VERSION ""

NS_ :

BS_:

BU_: C_LAM_01

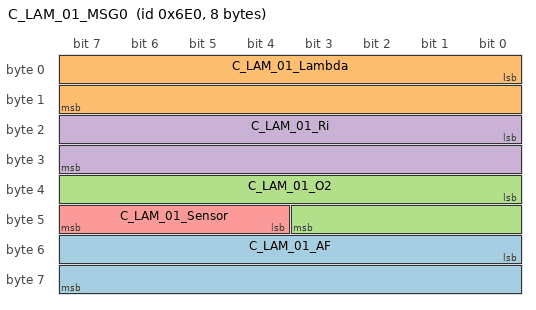
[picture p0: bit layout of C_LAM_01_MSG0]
BO_ 1760 C_LAM_01_MSG0: 8 C_LAM_01
 SG_ C_LAM_01_AF : 48|16@1+ (0.01,0) [0|0] "" Vector__XXX
 SG_ C_LAM_01_Lambda : 0|16@1+ (0.001,0) [0|0] "" Vector__XXX
 SG_ C_LAM_01_O2 : 32|12@1+ (0.01,0) [0|0] "%" Vector__XXX
 SG_ C_LAM_01_Ri : 16|16@1+ (0.1,0) [0|0] "Ohm" Vector__XXX
 SG_ C_LAM_01_Sensor : 44|4@1+ (1,0) [0|0] "" Vector__XXX

BO_ 1761 C_LAM_01_MSG1: 4 C_LAM_01
 SG_ C_LAM_01_Ip_In : 16|16@1- (0.0001,0) [0|0] "mA" Vector__XXX
 SG_ C_LAM_01_Ip : 0|16@1- (0.0001,0) [0|0] "mA" Vector__XXX
